# ATSAMA5D26 register map
Vendor: Microchip Technology; Series: SAMA5D2; File version: 0
Registers are 32-bit, read-write, reset 0x0 unless marked. A register's access mark holds for its fields unless they carry their own. Offsets are from the block's base; [hi:lo] are bit positions; {n}, {i} and the like mark numbered series.

## SCKC — Slow Clock Controller
Base 0xF8048050
0x00 CR — Slow Clock Controller Configuration Register
  [3] OSCSEL — Slow Clock Selector
    0=RC (Slow clock is the embedded 64 kHz (typical) RC oscillator.); 1=XTAL (Slow clock is the 32.768 kHz crystal oscillator.)

## SECUMOD — Security Module
Base 0xFC040000
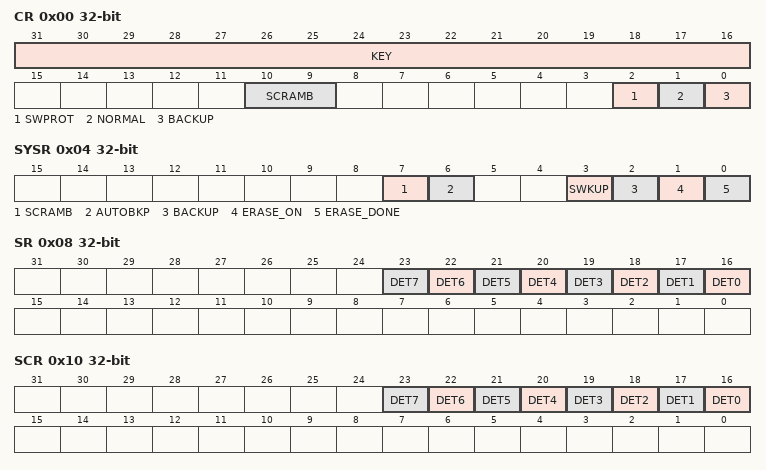
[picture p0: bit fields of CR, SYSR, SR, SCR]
0x00 CR wo — Control Register
  [31:16] KEY — Password
  [10:9] SCRAMB — Memory Scrambling Enable
  [2] SWPROT — Software Protection
  [1] NORMAL — Normal Mode
  [0] BACKUP — Backup Mode
0x04 SYSR — System Status Register
  [7] SCRAMB — Scrambling Enabled (RO)
  [6] AUTOBKP — Automatic Backup Mode Enabled (RO)
  [3] SWKUP — SWKUP State (RO)
  [2] BACKUP — Backup Mode (RO)
  [1] ERASE_ON — Erase Process Ongoing (RO)
  [0] ERASE_DONE — Erasable Memories State (RW)
0x08 SR ro — Status Register
  [n+16] DET{n} (n=0..7) — PIOBU Intrusion Detector
0x10 SCR wo — Status Clear Register
  [n+16] DET{n} (n=0..7) — PIOBU Intrusion Detector
0x14 RAMRDY ro — RAM Access Ready Register
  [0] READY — Ready for system access flag
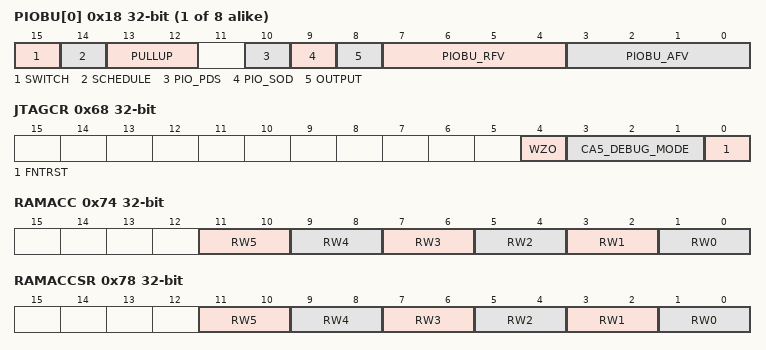
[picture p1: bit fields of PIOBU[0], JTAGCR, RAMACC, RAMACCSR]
{0x18+4i} PIOBU[{i}] (i=0..7) — PIO Backup Register
  [15] SWITCH — Switch State for Intrusion Detection
  [14] SCHEDULE — Pull-up/Down Scheduled
  [13:12] PULLUP — Programmable Pull-up State
  [10] PIO_PDS — Level on the Pin in Input Mode (OUTPUT = 0) (Read-only)
  [9] PIO_SOD — Set/Clear the I/O Line when configured in Output Mode (OUTPUT =1)
  [8] OUTPUT — Configure I/O Line in Input/Output
  [7:4] PIOBU_RFV — PIOBUx Reset Filter Value
  [3:0] PIOBU_AFV — PIOBU Alarm Filter Value
0x68 JTAGCR — JTAG Protection Control Register
  [4] WZO — Write ZERO
  [3:1] CA5_DEBUG_MODE — Cortex-A5 Invasive/Non-Invasive Secure/Non-Secure Debug Permissions
  [0] FNTRST — Force NTRST
0x70 SCRKEY — Scrambling Key Register
  [31:0] SCRKEY — Scrambling Key Value
0x74 RAMACC — RAM Access Rights Register
  [11:10] RW5 — Access right for RAM region [5 Kbytes; 6 Kbytes] (register bank BUREG256b)
  [9:8] RW4 — Access right for RAM region [4 Kbytes; 5 Kbytes]
  [7:6] RW3 — Access right for RAM region [3 Kbytes; 4 Kbytes]
  [5:4] RW2 — Access right for RAM region [2 Kbytes; 3 Kbytes]
  [3:2] RW1 — Access right for RAM region [1 Kbyte; 2 Kbytes]
  [1:0] RW0 — Access right for RAM region [0; 1 Kbyte]
0x78 RAMACCSR — RAM Access Rights Status Register
  [11:10] RW5 — Access right status for RAM region [5 Kbytes; 6 Kbytes] (register bank BUREG256b)
  [9:8] RW4 — Access right status for RAM region [4 Kbytes; 5 Kbytes]
  [7:6] RW3 — Access right status for RAM region [3 Kbytes; 4 Kbytes]
  [5:4] RW2 — Access right status for RAM region [2 Kbytes; 3 Kbytes]
  [3:2] RW1 — Access right status for RAM region [1 Kbytes; 2 Kbytes]
  [1:0] RW0 — Access right status for RAM region [0; 1 Kbyte]
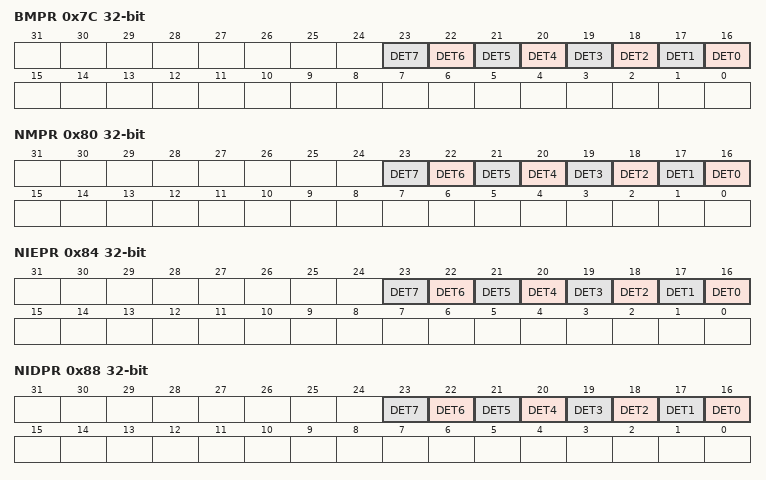
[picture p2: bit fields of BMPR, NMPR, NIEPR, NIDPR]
0x7C BMPR — Backup Mode Protection Register
  [n+16] DET{n} (n=0..7) — PIOBU Intrusion Detector Protection
0x80 NMPR — Normal Mode Protection Register
  [n+16] DET{n} (n=0..7) — PIOBU Intrusion Detector Protection
0x84 NIEPR wo — Normal Interrupt Enable Protection Register
  [n+16] DET{n} (n=0..7) — PIOBU Intrusion Detector Protection Interrupt Enable
0x88 NIDPR wo — Normal Interrupt Disable Protection Register
  [n+16] DET{n} (n=0..7) — PIOBU Intrusion Detector Protection Interrupt Disable
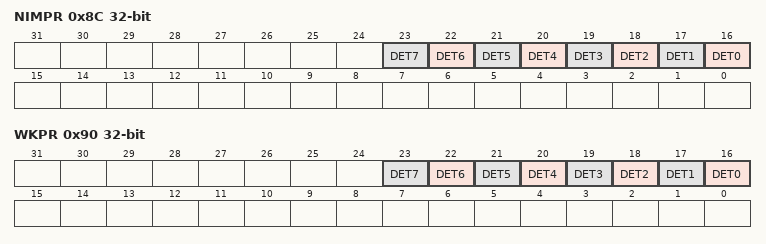
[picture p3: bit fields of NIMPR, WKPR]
0x8C NIMPR ro — Normal Interrupt Mask Protection Register
  [n+16] DET{n} (n=0..7) — PIOBU Intrusion Detector Protection Interrupt Mask
0x90 WKPR — Wakeup Protection Register
  [n+16] DET{n} (n=0..7) — PIOBU Intrusion Detector Protection

## SFC — Secure Fuse Controller
Base 0xF804C000
0x00 KR wo — SFC Key Register
  [7:0] KEY — Key Code
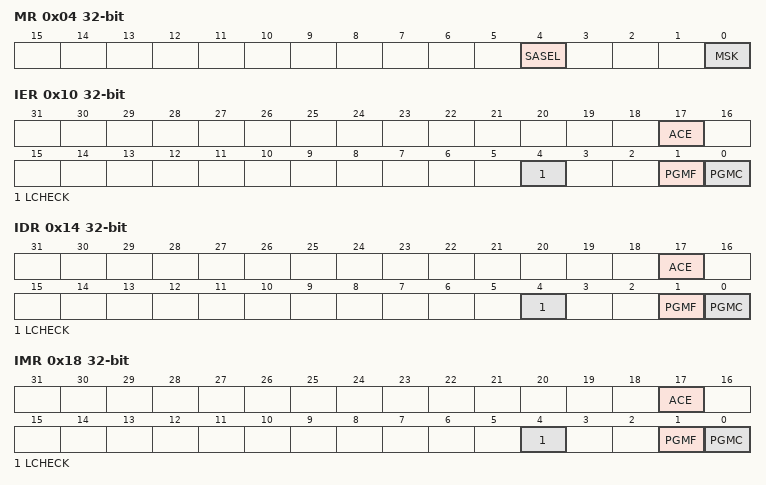
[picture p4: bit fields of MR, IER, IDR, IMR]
0x04 MR — SFC Mode Register
  [4] SASEL — Sense Amplifier Selection
  [0] MSK — Mask Data Registers
0x10 IER wo — SFC Interrupt Enable Register
  [17] ACE — Area Check Error Interrupt Enable
  [4] LCHECK — Live Integrity Check Error Interrupt Enable
  [1] PGMF — Programming Sequence Failed Interrupt Enable
  [0] PGMC — Programming Sequence Completed Interrupt Enable
0x14 IDR wo — SFC Interrupt Disable Register
  [17] ACE — Area Check Error Interrupt Disable
  [4] LCHECK — Live Integrity Check Error Interrupt Disable
  [1] PGMF — Programming Sequence Failed Interrupt Disable
  [0] PGMC — Programming Sequence Completed Interrupt Disable
0x18 IMR ro — SFC Interrupt Mask Register
  [17] ACE — Area Check Error Interrupt Mask
  [4] LCHECK — Live Integrity Checking Error Interrupt Mask
  [1] PGMF — Programming Sequence Failed Interrupt Mask
  [0] PGMC — Programming Sequence Completed Interrupt Mask
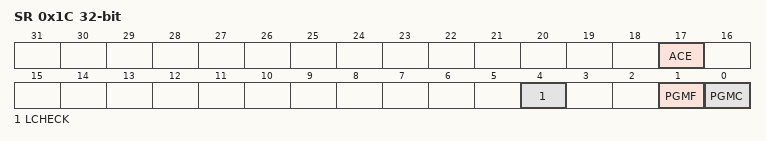
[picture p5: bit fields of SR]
0x1C SR ro — SFC Status Register
  [17] ACE — Area Check Error (cleared on read)
  [4] LCHECK — Live Integrity Checking Error (cleared on read)
  [1] PGMF — Programming Sequence Failed (cleared on read)
  [0] PGMC — Programming Sequence Completed (cleared on read)
{0x20+4i} DR[{i}] (i=0..16) — SFC Data Register
  [31:0] DATA — Fuse Data
